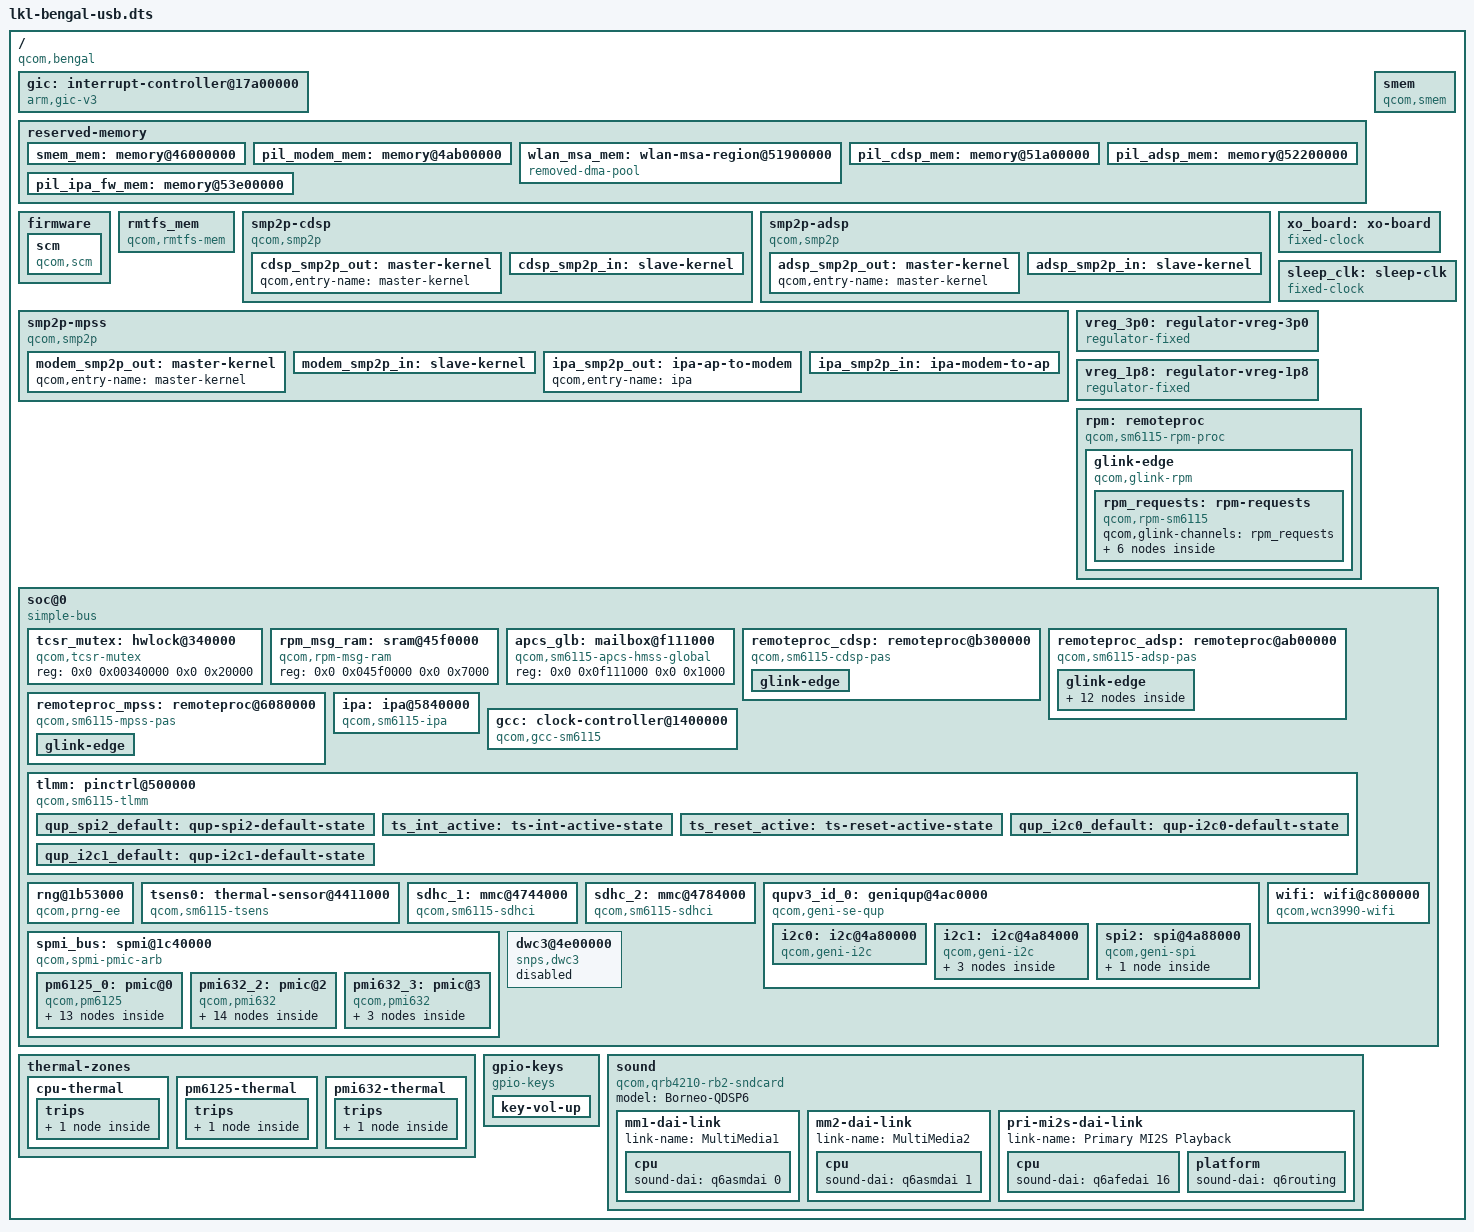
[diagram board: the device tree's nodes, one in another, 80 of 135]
/*
 * Device tree for Qualcomm Bengal / SM6115 (Moto G Power 2021 / borneo)
 * running under LKL: clocks, TLMM GPIO/pinctrl, PRNG, TSENS, eMMC/SD
 * (SDHCI), QUPv3 GENI (I2C/SPI), and DWC3 USB gadget.
 *
 * The bootloader leaves the SoC power rails and USB/storage PHYs powered
 * on, so fixed regulators represent the active rails where needed.
 */
/dts-v1/;

/ {
	compatible = "qcom,bengal", "qcom,sm6115";
	#address-cells = <2>;
	#size-cells = <2>;

	gic: interrupt-controller@17a00000 {
		compatible = "arm,gic-v3";
		reg = <0x0 0x17a00000 0x0 0x10000>,
		      <0x0 0x17a60000 0x0 0x100000>;
		interrupt-controller;
		#interrupt-cells = <3>;
		#address-cells = <0>;
	};

	reserved-memory {
		#address-cells = <2>;
		#size-cells = <2>;
		ranges;

		smem_mem: memory@46000000 {
			reg = <0x0 0x46000000 0x0 0x200000>;
			no-map;
		};

		pil_modem_mem: memory@4ab00000 {
			no-map;
			reg = <0x0 0x4ab00000 0x0 0x6900000>;
		};

		wlan_msa_mem: wlan-msa-region@51900000 {
			compatible = "removed-dma-pool";
			no-map;
			reg = <0x0 0x51900000 0x0 0x100000>;
		};

		pil_cdsp_mem: memory@51a00000 {
			no-map;
			reg = <0x0 0x51a00000 0x0 0x800000>;
		};

		pil_adsp_mem: memory@52200000 {
			no-map;
			reg = <0x0 0x52200000 0x0 0x1c00000>;
		};

		pil_ipa_fw_mem: memory@53e00000 {
			no-map;
			reg = <0x0 0x53e00000 0x0 0x10000>;
		};
	};

	firmware {
		scm: scm {
			compatible = "qcom,scm";
			#reset-cells = <1>;
		};
	};

	smem {
		compatible = "qcom,smem";
		memory-region = <&smem_mem>;
		hwlocks = <&tcsr_mutex 3>;
	};

	rmtfs_mem {
		compatible = "qcom,rmtfs-mem";
		qcom,client-id = <1>;
		qcom,vmid = <15 43>;
	};

	smp2p-cdsp {
		compatible = "qcom,smp2p";
		qcom,smem = <94>, <432>;
		interrupt-parent = <&gic>;
		interrupts = <0 263 1>;
		mboxes = <&apcs_glb 30>;
		qcom,local-pid = <0>;
		qcom,remote-pid = <5>;

		cdsp_smp2p_out: master-kernel {
			qcom,entry-name = "master-kernel";
			#qcom,smem-state-cells = <1>;
		};

		cdsp_smp2p_in: slave-kernel {
			qcom,entry-name = "slave-kernel";
			interrupt-controller;
			#interrupt-cells = <2>;
		};
	};

	smp2p-adsp {
		compatible = "qcom,smp2p";
		qcom,smem = <443>, <429>;
		interrupt-parent = <&gic>;
		interrupts = <0 279 1>;
		mboxes = <&apcs_glb 10>;
		qcom,local-pid = <0>;
		qcom,remote-pid = <2>;

		adsp_smp2p_out: master-kernel {
			qcom,entry-name = "master-kernel";
			#qcom,smem-state-cells = <1>;
		};

		adsp_smp2p_in: slave-kernel {
			qcom,entry-name = "slave-kernel";
			interrupt-controller;
			#interrupt-cells = <2>;
		};
	};

	smp2p-mpss {
		compatible = "qcom,smp2p";
		qcom,smem = <435>, <428>;
		interrupt-parent = <&gic>;
		interrupts = <0 70 1>;
		mboxes = <&apcs_glb 14>;
		qcom,local-pid = <0>;
		qcom,remote-pid = <1>;

		modem_smp2p_out: master-kernel {
			qcom,entry-name = "master-kernel";
			#qcom,smem-state-cells = <1>;
		};

		modem_smp2p_in: slave-kernel {
			qcom,entry-name = "slave-kernel";
			interrupt-controller;
			#interrupt-cells = <2>;
		};

		ipa_smp2p_out: ipa-ap-to-modem {
			qcom,entry-name = "ipa";
			#qcom,smem-state-cells = <1>;
		};

		ipa_smp2p_in: ipa-modem-to-ap {
			qcom,entry-name = "ipa";
			interrupt-controller;
			#interrupt-cells = <2>;
		};
	};

	xo_board: xo-board {
		compatible = "fixed-clock";
		#clock-cells = <0>;
		clock-frequency = <19200000>;
		clock-output-names = "xo_board";
	};

	sleep_clk: sleep-clk {
		compatible = "fixed-clock";
		#clock-cells = <0>;
		clock-frequency = <32768>;
		clock-output-names = "sleep_clk";
	};

	vreg_3p0: regulator-vreg-3p0 {
		compatible = "regulator-fixed";
		regulator-name = "vreg_3p0";
		regulator-min-microvolt = <2960000>;
		regulator-max-microvolt = <2960000>;
		regulator-always-on;
	};

	vreg_1p8: regulator-vreg-1p8 {
		compatible = "regulator-fixed";
		regulator-name = "vreg_1p8";
		regulator-min-microvolt = <1800000>;
		regulator-max-microvolt = <1800000>;
		regulator-always-on;
	};

	rpm: remoteproc {
		compatible = "qcom,sm6115-rpm-proc", "qcom,rpm-proc";

		glink-edge {
			compatible = "qcom,glink-rpm";
			interrupt-parent = <&gic>;
			interrupts = <0 194 1>;
			qcom,rpm-msg-ram = <&rpm_msg_ram>;
			mboxes = <&apcs_glb 0>;

			rpm_requests: rpm-requests {
				compatible = "qcom,rpm-sm6115", "qcom,glink-smd-rpm";
				qcom,glink-channels = "rpm_requests";

				rpmcc: clock-controller {
					compatible = "qcom,rpmcc-sm6115", "qcom,rpmcc";
					#clock-cells = <1>;
				};

				regulators-0 {
					compatible = "qcom,rpm-pm6125-regulators";

					pm6125_l8: l8 {
						regulator-min-microvolt = <400000>;
						regulator-max-microvolt = <728000>;
					};

					pm6125_l16: l16 {
						regulator-min-microvolt = <1704000>;
						regulator-max-microvolt = <1904000>;
					};

					pm6125_l17: l17 {
						regulator-min-microvolt = <1152000>;
						regulator-max-microvolt = <1384000>;
					};

					pm6125_l23: l23 {
						regulator-min-microvolt = <3200000>;
						regulator-max-microvolt = <3400000>;
					};
				};
			};
		};
	};

	soc@0 {
		compatible = "simple-bus";
		#address-cells = <2>;
		#size-cells = <2>;
		ranges;

		tcsr_mutex: hwlock@340000 {
			compatible = "qcom,tcsr-mutex";
			reg = <0x0 0x00340000 0x0 0x20000>;
			#hwlock-cells = <1>;
		};

		rpm_msg_ram: sram@45f0000 {
			compatible = "qcom,rpm-msg-ram";
			reg = <0x0 0x045f0000 0x0 0x7000>;
		};

		apcs_glb: mailbox@f111000 {
			compatible = "qcom,sm6115-apcs-hmss-global",
				     "qcom,msm8994-apcs-kpss-global";
			reg = <0x0 0x0f111000 0x0 0x1000>;
			#mbox-cells = <1>;
		};

		remoteproc_cdsp: remoteproc@b300000 {
			compatible = "qcom,sm6115-cdsp-pas";
			interrupts-extended = <&gic 0 265 1>,
					      <&cdsp_smp2p_in 0 1>,
					      <&cdsp_smp2p_in 1 1>,
					      <&cdsp_smp2p_in 2 1>,
					      <&cdsp_smp2p_in 3 1>;
			interrupt-names = "wdog", "fatal", "ready",
					  "handover", "stop-ack";
			clocks = <&xo_board>;
			clock-names = "xo";
			memory-region = <&pil_cdsp_mem>;
			qcom,smem-states = <&cdsp_smp2p_out 0>;
			qcom,smem-state-names = "stop";
			status = "okay";

			glink-edge {
				interrupt-parent = <&gic>;
				interrupts = <0 261 1>;
				label = "cdsp";
				qcom,remote-pid = <5>;
				mboxes = <&apcs_glb 28>;
			};
		};

		remoteproc_adsp: remoteproc@ab00000 {
			compatible = "qcom,sm6115-adsp-pas";
			interrupts-extended = <&gic 0 282 1>,
					      <&adsp_smp2p_in 0 1>,
					      <&adsp_smp2p_in 1 1>,
					      <&adsp_smp2p_in 2 1>,
					      <&adsp_smp2p_in 3 1>;
			interrupt-names = "wdog", "fatal", "ready",
					  "handover", "stop-ack";
			clocks = <&xo_board>;
			clock-names = "xo";
			memory-region = <&pil_adsp_mem>;
			qcom,smem-states = <&adsp_smp2p_out 0>;
			qcom,smem-state-names = "stop";
			status = "okay";

			glink-edge {
				interrupt-parent = <&gic>;
				interrupts = <0 277 1>;
				label = "lpass";
				qcom,remote-pid = <2>;
				mboxes = <&apcs_glb 8>;

				apr {
					compatible = "qcom,apr-v2";
					qcom,glink-channels = "apr_audio_svc";
					qcom,domain = <4>;	/* APR_DOMAIN_ADSP */
					#address-cells = <1>;
					#size-cells = <0>;
					qcom,intents = <512 20>;

					q6core: service@3 {
						reg = <3>;	/* APR_SVC_ADSP_CORE */
						compatible = "qcom,q6core";
						qcom,protection-domain = "avs/audio", "msm/adsp/audio_pd";
					};

					q6afe: service@4 {
						reg = <4>;	/* APR_SVC_AFE */
						compatible = "qcom,q6afe";
						qcom,protection-domain = "avs/audio", "msm/adsp/audio_pd";

						q6afedai: dais {
							compatible = "qcom,q6afe-dais";
							#address-cells = <1>;
							#size-cells = <0>;
							#sound-dai-cells = <1>;
						};

						q6afecc: clock-controller {
							compatible = "qcom,q6afe-clocks";
							#clock-cells = <2>;
						};
					};

					q6asm: service@7 {
						reg = <7>;	/* APR_SVC_ASM */
						compatible = "qcom,q6asm";
						qcom,protection-domain = "avs/audio", "msm/adsp/audio_pd";

						q6asmdai: dais {
							compatible = "qcom,q6asm-dais";
							#address-cells = <1>;
							#size-cells = <0>;
							#sound-dai-cells = <1>;

							dai@0 {
								reg = <0>;
								direction = <2>;	/* Q6ASM_DAI_RX */
							};

							dai@1 {
								reg = <1>;
								direction = <1>;	/* Q6ASM_DAI_TX */
							};

							dai@2 {
								reg = <2>;
								direction = <0>;	/* Q6ASM_DAI_TX_RX */
							};
						};
					};

					q6adm: service@8 {
						reg = <8>;	/* APR_SVC_ADM */
						compatible = "qcom,q6adm";
						qcom,protection-domain = "avs/audio", "msm/adsp/audio_pd";

						q6routing: routing {
							compatible = "qcom,q6adm-routing";
							#sound-dai-cells = <0>;
						};
					};
				};
			};
		};

		remoteproc_mpss: remoteproc@6080000 {
			compatible = "qcom,sm6115-mpss-pas";
			interrupts-extended = <&gic 0 307 1>,
					      <&modem_smp2p_in 0 1>,
					      <&modem_smp2p_in 1 1>,
					      <&modem_smp2p_in 2 1>,
					      <&modem_smp2p_in 3 1>,
					      <&modem_smp2p_in 7 1>;
			interrupt-names = "wdog", "fatal", "ready",
					  "handover", "stop-ack", "shutdown-ack";
			clocks = <&xo_board>;
			clock-names = "xo";
			memory-region = <&pil_modem_mem>;
			qcom,smem-states = <&modem_smp2p_out 0>;
			qcom,smem-state-names = "stop";
			status = "okay";

			glink-edge {
				interrupt-parent = <&gic>;
				interrupts = <0 68 1>;
				label = "mpss";
				qcom,remote-pid = <1>;
				mboxes = <&apcs_glb 12>;
			};
		};

		ipa: ipa@5840000 {
			compatible = "qcom,sm6115-ipa";
			reg = <0x0 0x05840000 0x0 0x7000>,
			      <0x0 0x05847000 0x0 0x2000>,
			      <0x0 0x05804000 0x0 0x28000>;
			reg-names = "ipa-reg", "ipa-shared", "gsi";
			interrupts-extended = <&gic 0 257 4>,
					      <&gic 0 259 4>,
					      <&ipa_smp2p_in 0 1>,
					      <&ipa_smp2p_in 1 1>;
			interrupt-names = "ipa", "gsi",
					  "ipa-clock-query", "ipa-setup-ready";
			clocks = <&rpmcc 68>;
			clock-names = "core";
			memory-region = <&pil_ipa_fw_mem>;
			qcom,smem-states = <&ipa_smp2p_out 0>,
					   <&ipa_smp2p_out 1>;
			qcom,smem-state-names = "ipa-clock-enabled-valid",
						"ipa-clock-enabled";
			status = "okay";
		};

		gcc: clock-controller@1400000 {
			compatible = "qcom,gcc-sm6115";
			reg = <0x0 0x01400000 0x0 0x1f0000>;
			clocks = <&xo_board>, <&sleep_clk>;
			clock-names = "bi_tcxo", "sleep_clk";
			#clock-cells = <1>;
			#reset-cells = <1>;
			#power-domain-cells = <1>;
			status = "okay";
		};

		tlmm: pinctrl@500000 {
			compatible = "qcom,sm6115-tlmm";
			reg = <0x0 0x00500000 0x0 0x400000>,
			      <0x0 0x00900000 0x0 0x400000>,
			      <0x0 0x00d00000 0x0 0x300000>;
			reg-names = "west", "south", "east";
			interrupt-parent = <&gic>;
			interrupts = <0 227 4>;
			gpio-controller;
			gpio-ranges = <&tlmm 0 0 114>;
			gpio-reserved-ranges = <14 4>;
			#gpio-cells = <2>;
			interrupt-controller;
			#interrupt-cells = <2>;
			status = "okay";

			qup_spi2_default: qup-spi2-default-state {
				pins = "gpio6", "gpio7", "gpio71", "gpio80";
				function = "qup2";
				drive-strength = <6>;
				bias-pull-up;
			};

			ts_int_active: ts-int-active-state {
				pins = "gpio67";
				function = "gpio";
				drive-strength = <8>;
				bias-pull-up;
				input-enable;
			};

			ts_reset_active: ts-reset-active-state {
				pins = "gpio66";
				function = "gpio";
				drive-strength = <8>;
				bias-pull-up;
			};

			qup_i2c0_default: qup-i2c0-default-state {
				pins = "gpio0", "gpio1";
				function = "qup0";
				drive-strength = <2>;
				bias-disable;
			};

			qup_i2c1_default: qup-i2c1-default-state {
				pins = "gpio4", "gpio5";
				function = "qup1";
				drive-strength = <2>;
				bias-disable;
			};
		};

		rng@1b53000 {
			compatible = "qcom,prng-ee";
			reg = <0x0 0x01b53000 0x0 0x1000>;
			clocks = <&gcc 84>;
			clock-names = "core";
			status = "okay";
		};

		tsens0: thermal-sensor@4411000 {
			compatible = "qcom,sm6115-tsens", "qcom,tsens-v2";
			reg = <0x0 0x04411000 0x0 0x1ff>,
			      <0x0 0x04410000 0x0 0x8>;
			interrupt-parent = <&gic>;
			interrupts = <0 275 4>, <0 190 4>;
			interrupt-names = "uplow", "critical";
			#qcom,sensors = <16>;
			#thermal-sensor-cells = <1>;
			status = "okay";
		};

		sdhc_1: mmc@4744000 {
			compatible = "qcom,sm6115-sdhci", "qcom,sdhci-msm-v5";
			reg = <0x0 0x04744000 0x0 0x1000>;
			reg-names = "hc";
			interrupt-parent = <&gic>;
			interrupts = <0 348 4>, <0 352 4>;
			interrupt-names = "hc_irq", "pwr_irq";
			clocks = <&gcc 106>, <&gcc 107>, <&xo_board>;
			clock-names = "iface", "core", "xo";
			vmmc-supply = <&vreg_3p0>;
			vqmmc-supply = <&vreg_1p8>;
			bus-width = <8>;
			non-removable;
			mmc-hs400-1_8v;
			mmc-hs200-1_8v;
			status = "okay";
		};

		sdhc_2: mmc@4784000 {
			compatible = "qcom,sm6115-sdhci", "qcom,sdhci-msm-v5";
			reg = <0x0 0x04784000 0x0 0x1000>;
			reg-names = "hc";
			interrupt-parent = <&gic>;
			interrupts = <0 350 4>, <0 353 4>;
			interrupt-names = "hc_irq", "pwr_irq";
			clocks = <&gcc 111>, <&gcc 112>, <&xo_board>;
			clock-names = "iface", "core", "xo";
			vmmc-supply = <&vreg_3p0>;
			vqmmc-supply = <&vreg_1p8>;
			bus-width = <4>;
			cd-gpios = <&tlmm 88 0>;
			status = "okay";
		};

		qupv3_id_0: geniqup@4ac0000 {
			compatible = "qcom,geni-se-qup";
			reg = <0x0 0x04ac0000 0x0 0x2000>;
			clocks = <&gcc 104>, <&gcc 105>;
			clock-names = "m-ahb", "s-ahb";
			#address-cells = <2>;
			#size-cells = <2>;
			ranges;
			status = "okay";

			i2c0: i2c@4a80000 {
				pinctrl-names = "default";
				pinctrl-0 = <&qup_i2c0_default>;
				compatible = "qcom,geni-i2c";
				reg = <0x0 0x04a80000 0x0 0x4000>;
				interrupt-parent = <&gic>;
				interrupts = <0 327 4>;
				clocks = <&gcc 92>;
				clock-names = "se";
				#address-cells = <1>;
				#size-cells = <0>;
				status = "okay";
			};

			i2c1: i2c@4a84000 {
				pinctrl-names = "default";
				pinctrl-0 = <&qup_i2c1_default>;
				compatible = "qcom,geni-i2c";
				reg = <0x0 0x04a84000 0x0 0x4000>;
				interrupt-parent = <&gic>;
				interrupts = <0 328 4>;
				clocks = <&gcc 94>;
				clock-names = "se";
				#address-cells = <1>;
				#size-cells = <0>;
				status = "okay";

				aw88261: speaker-amp@34 {
					/* Instantiate post-boot via i2c-1/new_device once IRQ 360 is watched */
					compatible = "awinic,aw88261";
					reg = <0x34>;
					#sound-dai-cells = <0>;
					status = "disabled";
				};

				lm3697: lm3697@37 {
					/* Bisect: enabling this at stage 4 coincided
					 * with a watchdog fallback (boot4).  Keep
					 * disabled until the LKL-rebuild question
					 * is settled, then re-enable. */
					status = "disabled";
					lm3697,stage-limit = <4>;
					compatible = "ti,lm3697";
					reg = <0x37>;
					enable-gpios = <&pmi632_gpios 6 0>;
					#address-cells = <1>;
					#size-cells = <0>;

					led@0 {
						reg = <0>;
						led-sources = <0 1 2>;
						function = "backlight";
						default-state = "on";
					};
				};
			};

			spi2: spi@4a88000 {
				compatible = "qcom,geni-spi";
				reg = <0x0 0x04a88000 0x0 0x4000>;
				interrupt-parent = <&gic>;
				interrupts = <0 329 4>;
				clocks = <&gcc 96>;
				clock-names = "se";
				#address-cells = <1>;
				#size-cells = <0>;
				pinctrl-names = "default";
				pinctrl-0 = <&qup_spi2_default>;
				status = "okay";

				focaltech@0 {
					compatible = "focaltech,fts";
					reg = <0>;
					pinctrl-names = "default";
					pinctrl-0 = <&ts_int_active &ts_reset_active>;
					spi-max-frequency = <2000000>;
					focaltech,always_on_vio;
					focaltech,share_reset_gpio;
					focaltech,reset-gpio = <&tlmm 66 1>;
					focaltech,irq-gpio = <&tlmm 67 2>;
					focaltech,max-touch-number = <10>;
					focaltech,display-coords = <0 0 720 1600>;
					focaltech,stage-limit = <10>;
					focaltech,name = "ft8009";
					focaltech,family-id = <0xf0>;
					focaltech,panel-supplier = "djnboe";
					focaltech,report_gesture_key;
					focaltech,dlfw_in_resume;
				};
			};
		};

		spmi_bus: spmi@1c40000 {
			compatible = "qcom,spmi-pmic-arb";
			reg = <0x0 0x01c40000 0x0 0x1100>,
			      <0x0 0x01e00000 0x0 0x2000000>,
			      <0x0 0x03e00000 0x0 0x100000>,
			      <0x0 0x03f00000 0x0 0xa0000>,
			      <0x0 0x01c0a000 0x0 0x26000>;
			reg-names = "core", "chnls", "obsrvr", "intr", "cnfg";
			interrupt-parent = <&gic>;
			interrupt-names = "periph_irq";
			interrupts = <0 183 4>;
			qcom,ee = <0>;
			qcom,channel = <0>;
			#address-cells = <2>;
			#size-cells = <0>;
			interrupt-controller;
			#interrupt-cells = <4>;
			status = "okay";

			pm6125_0: pmic@0 {
				compatible = "qcom,pm6125", "qcom,spmi-pmic";
				reg = <0x0 0>;
				interrupt-parent = <&spmi_bus>;
				#address-cells = <1>;
				#size-cells = <0>;

				pm6125_pon: pon@800 {
					compatible = "qcom,pm8998-pon";
					reg = <0x800>;
					mode-bootloader = <0x2>;
					mode-recovery = <0x1>;
					pwrkey {
						compatible = "qcom,pm8941-pwrkey";
						interrupts = <0x0 0x8 0 3>;
						debounce = <15625>;
						bias-pull-up;
						linux,code = <116>;
					};

					resin {
						compatible = "qcom,pm8941-resin";
						interrupts = <0x0 0x8 1 3>;
						debounce = <15625>;
						bias-pull-up;
						linux,code = <114>;	/* KEY_VOLUMEDOWN */
					};
				};

				pm6125_rtc: rtc@6000 {
					compatible = "qcom,pm8941-rtc";
					reg = <0x6000>;
					interrupts = <0x0 0x61 0x1 0>;
				};

				pm6125_temp: temp-alarm@2400 {
					compatible = "qcom,spmi-temp-alarm";
					reg = <0x2400>;
					interrupts = <0x0 0x24 0 3>;
					#thermal-sensor-cells = <0>;
				};

				pm6125_adc: adc@3100 {
					compatible = "qcom,spmi-adc5";
					reg = <0x3100>;
					interrupts = <0x0 0x31 0 1>;
					#address-cells = <1>;
					#size-cells = <0>;
					#io-channel-cells = <1>;

					channel@0 {
						reg = <0x00>;
						label = "ref_gnd";
						qcom,pre-scaling = <1 1>;
					};
					channel@1 {
						reg = <0x01>;
						label = "vref_1p25";
						qcom,pre-scaling = <1 1>;
					};
					channel@6 {
						reg = <0x06>;
						label = "die_temp";
						qcom,pre-scaling = <1 1>;
					};
					channel@83 {
						reg = <0x83>;
						label = "vph_pwr";
						qcom,pre-scaling = <1 3>;
					};
					channel@85 {
						reg = <0x85>;
						label = "vcoin";
						qcom,pre-scaling = <1 3>;
					};
					channel@4c {
						reg = <0x4c>;
						label = "xo_therm";
						qcom,pre-scaling = <1 1>;
						qcom,hw-settle-time = <200>;
						qcom,ratiometric;
					};
				};

				pm6125_gpios: gpio@c000 {
					compatible = "qcom,pm6125-gpio", "qcom,spmi-gpio";
					reg = <0xc000>;
					gpio-controller;
					#gpio-cells = <2>;
					interrupt-controller;
					#interrupt-cells = <2>;
				};
			};

			pmi632_2: pmic@2 {
				compatible = "qcom,pmi632", "qcom,spmi-pmic";
				reg = <0x2 0>;
				interrupt-parent = <&spmi_bus>;
				#address-cells = <1>;
				#size-cells = <0>;

				pmi632_temp: temp-alarm@2400 {
					compatible = "qcom,spmi-temp-alarm";
					reg = <0x2400>;
					interrupts = <0x2 0x24 0 3>;
					#thermal-sensor-cells = <0>;
				};

				pmi632_adc: adc@3100 {
					compatible = "qcom,spmi-adc5";
					reg = <0x3100>;
					interrupts = <0x2 0x31 0 1>;
					#address-cells = <1>;
					#size-cells = <0>;
					#io-channel-cells = <1>;

					channel@0 {
						reg = <0x00>;
						label = "ref_gnd";
						qcom,pre-scaling = <1 1>;
					};
					channel@1 {
						reg = <0x01>;
						label = "vref_1p25";
						qcom,pre-scaling = <1 1>;
					};
					channel@6 {
						reg = <0x06>;
						label = "die_temp";
						qcom,pre-scaling = <1 1>;
					};
					channel@83 {
						reg = <0x83>;
						label = "vph_pwr";
						qcom,pre-scaling = <1 3>;
					};
					channel@84 {
						reg = <0x84>;
						label = "vbat_sns";
						qcom,pre-scaling = <1 3>;
					};
					channel@8 {
						reg = <0x08>;
						label = "usb_in_v_div_16";
						qcom,pre-scaling = <1 16>;
					};
					channel@7 {
						reg = <0x07>;
						label = "usb_in_i_uv";
						qcom,pre-scaling = <1 1>;
					};
					channel@9 {
						reg = <0x09>;
						label = "chg_temp";
						qcom,pre-scaling = <1 1>;
					};
					channel@4b {
						reg = <0x4b>;
						label = "bat_id";
						qcom,hw-settle-time = <200>;
						qcom,pre-scaling = <1 1>;
						qcom,ratiometric;
					};
				};

				pmi632_pbs_client3: pbs@7400 {
					compatible = "qcom,pmi632-pbs", "qcom,pbs";
					reg = <0x7400>;
				};

				pmi632_sdam_7: nvram@b600 {
					compatible = "qcom,spmi-sdam";
					reg = <0xb600>;
					#address-cells = <1>;
					#size-cells = <1>;
					ranges = <0 0xb600 0x100>;
				};

				pmi632_gpios: gpio@c000 {
					compatible = "qcom,pmi632-gpio", "qcom,spmi-gpio";
					reg = <0xc000>;
					gpio-controller;
					#gpio-cells = <2>;
					interrupt-controller;
					#interrupt-cells = <2>;
				};
			};

			pmi632_3: pmic@3 {
				compatible = "qcom,pmi632", "qcom,spmi-pmic";
				reg = <0x3 0>;
				interrupt-parent = <&spmi_bus>;
				#address-cells = <1>;
				#size-cells = <0>;

				pmi632_lpg: pwm {
					compatible = "qcom,pmi632-lpg";
					nvmem = <&pmi632_sdam_7>;
					nvmem-names = "lpg_chan_sdam";
					qcom,pbs = <&pmi632_pbs_client3>;
					#address-cells = <1>;
					#size-cells = <0>;
					#pwm-cells = <2>;

					led@1 {
						reg = <1>;
						color = <1>;	/* LED_COLOR_ID_RED */
						label = "charging";
					};
				};

				pmi632_vib: vibrator@5700 {
					compatible = "qcom,pmi632-vib";
					reg = <0x5700>;
				};
			};
		};

		wifi: wifi@c800000 {
			compatible = "qcom,wcn3990-wifi";
			reg = <0x0 0x0c800000 0x0 0x800000>;
			reg-names = "membase";
			memory-region = <&wlan_msa_mem>;
			interrupt-parent = <&gic>;
			interrupts = <0 358 4>, <0 359 4>, <0 360 4>,
				     <0 361 4>, <0 362 4>, <0 363 4>,
				     <0 364 4>, <0 365 4>, <0 366 4>,
				     <0 367 4>, <0 368 4>, <0 369 4>;
			qcom,msa-fixed-perm;
			vdd-0.8-cx-mx-supply = <&pm6125_l8>;
			vdd-1.8-xo-supply = <&pm6125_l16>;
			vdd-1.3-rfa-supply = <&pm6125_l17>;
			vdd-3.3-ch0-supply = <&pm6125_l23>;
			status = "okay";
		};

		dwc3@4e00000 {
			compatible = "snps,dwc3";
			reg = <0x0 0x4e00000 0x0 0xcd00>;
			interrupt-parent = <&gic>;
			interrupts = <0 255 4>;
			dr_mode = "peripheral";
			maximum-speed = "high-speed";
			snps,disable-clk-gating;
			snps,dis_u2_susphy_quirk;
			snps,dis_enblslpm_quirk;
			snps,has-lpm-erratum;
			snps,hird-threshold = [10];
			/* owned by the bengal_ctl control guest */
			status = "disabled";
		};
	};

	thermal-zones {
		cpu-thermal {
			polling-delay-passive = <250>;
			polling-delay = <1000>;
			thermal-sensors = <&tsens0 0>;

			trips {
				cpu-crit {
					temperature = <110000>;
					hysteresis = <1000>;
					type = "critical";
				};
			};
		};

		pm6125-thermal {
			polling-delay-passive = <0>;
			polling-delay = <0>;
			thermal-sensors = <&pm6125_temp>;

			trips {
				pm6125-trip0 {
					temperature = <95000>;
					hysteresis = <0>;
					type = "passive";
				};
			};
		};

		pmi632-thermal {
			polling-delay-passive = <0>;
			polling-delay = <0>;
			thermal-sensors = <&pmi632_temp>;

			trips {
				pmi632-trip0 {
					temperature = <95000>;
					hysteresis = <0>;
					type = "passive";
				};
			};
		};
	};

	gpio-keys {
		compatible = "gpio-keys";

		key-vol-up {
			label = "volume_up";
			gpios = <&pm6125_gpios 5 1>;	/* GPIO_ACTIVE_LOW */
			linux,code = <115>;		/* KEY_VOLUMEUP */
			debounce-interval = <15>;
		};
	};

	sound {
		compatible = "qcom,qrb4210-rb2-sndcard";
		model = "Borneo-QDSP6";

		mm1-dai-link {
			link-name = "MultiMedia1";
			cpu {
				sound-dai = <&q6asmdai 0>;	/* MSM_FRONTEND_DAI_MULTIMEDIA1 */
			};
		};

		mm2-dai-link {
			link-name = "MultiMedia2";
			cpu {
				sound-dai = <&q6asmdai 1>;	/* MSM_FRONTEND_DAI_MULTIMEDIA2 */
			};
		};

		pri-mi2s-dai-link {
			link-name = "Primary MI2S Playback";
			cpu {
				sound-dai = <&q6afedai 16>;	/* PRIMARY_MI2S_RX */
			};
			platform {
				sound-dai = <&q6routing>;
			};
		};
	};
};
